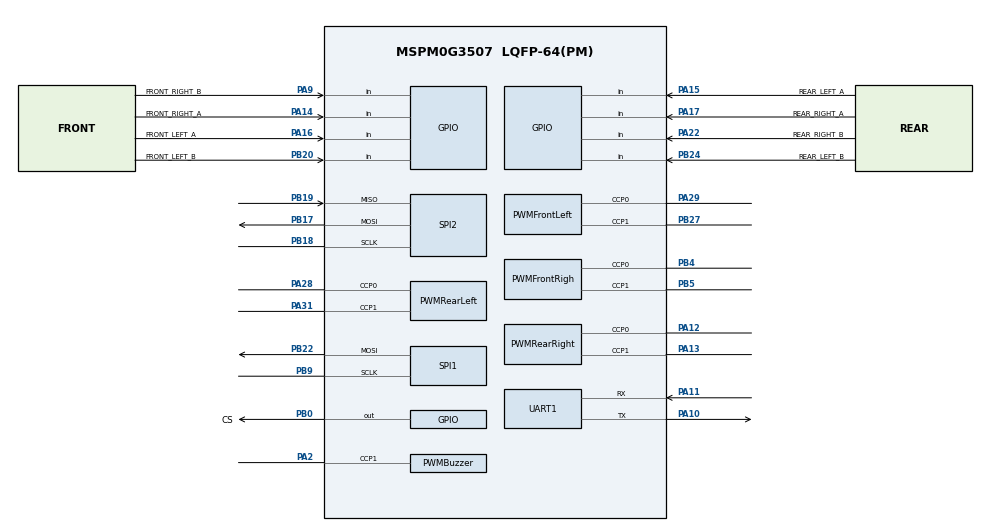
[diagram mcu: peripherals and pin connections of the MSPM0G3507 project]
/**
 * MSPM0G3507 application SysConfig source.
 * Generated files are written only to this project's Debug directory.
 * @cliArgs --device "MSPM0G350X" --package "LQFP-64(PM)" --part "Default" --product "mspm0_sdk@2.11.00.07"
 * @v2CliArgs --device "MSPM0G3507" --package "LQFP-64(PM)" --product "mspm0_sdk@2.11.00.07"
 */
const Board = scripting.addModule("/ti/driverlib/Board", {}, false);
const GPIO = scripting.addModule("/ti/driverlib/GPIO", {}, false);
const GPIO1 = GPIO.addInstance();
const GPIO2 = GPIO.addInstance();
const GPIO3 = GPIO.addInstance();
const PWM = scripting.addModule("/ti/driverlib/PWM", {}, false);
const PWMFrontLeft = PWM.addInstance();
const PWMFrontRight = PWM.addInstance();
const PWMRearLeft = PWM.addInstance();
const PWMRearRight = PWM.addInstance();
const PWMBuzzer = PWM.addInstance();
const SPI = scripting.addModule("/ti/driverlib/SPI", {}, false);
const SPI1 = SPI.addInstance();
const SPI2 = SPI.addInstance();
const SYSCTL = scripting.addModule("/ti/driverlib/SYSCTL");
const UART = scripting.addModule("/ti/driverlib/UART", {}, false);
const UART1 = UART.addInstance();
const hfxT = system.clockTree["HFXT"];
const pllQDiv = system.clockTree["PLL_QDIV"];
const hsclkMux = system.clockTree["HSCLKMUX"];
const ulpDiv = system.clockTree["UDIV"];

hfxT.inputFreq = 40;
hfxT.enable = true;
pllQDiv.multiplyValue = 5;
hsclkMux.inputSelect = "HSCLKMUX_SYSPLL0";
ulpDiv.divideValue = 2;

Board.configureUnused = true;
GPIO2.$name = "ENCODER";
GPIO2.associatedPins.create(8);
GPIO2.associatedPins[0].$name = "FRONT_LEFT_A";
GPIO2.associatedPins[0].direction = "INPUT";
GPIO2.associatedPins[0].interruptEn = true;
GPIO2.associatedPins[0].polarity = "RISE_FALL";
GPIO2.associatedPins[0].internalResistor = "PULL_UP";
GPIO2.associatedPins[0].pin.$assign = "PA16";
GPIO2.associatedPins[1].$name = "FRONT_LEFT_B";
GPIO2.associatedPins[1].direction = "INPUT";
GPIO2.associatedPins[1].internalResistor = "PULL_UP";
GPIO2.associatedPins[1].pin.$assign = "PB20";
GPIO2.associatedPins[2].$name = "FRONT_RIGHT_A";
GPIO2.associatedPins[2].direction = "INPUT";
GPIO2.associatedPins[2].interruptEn = true;
GPIO2.associatedPins[2].polarity = "RISE_FALL";
GPIO2.associatedPins[2].internalResistor = "PULL_UP";
GPIO2.associatedPins[2].pin.$assign = "PA14";
GPIO2.associatedPins[3].$name = "FRONT_RIGHT_B";
GPIO2.associatedPins[3].direction = "INPUT";
GPIO2.associatedPins[3].internalResistor = "PULL_UP";
GPIO2.associatedPins[3].pin.$assign = "PA9";
GPIO2.associatedPins[4].$name = "REAR_LEFT_A";
GPIO2.associatedPins[4].direction = "INPUT";
GPIO2.associatedPins[4].interruptEn = true;
GPIO2.associatedPins[4].polarity = "RISE_FALL";
GPIO2.associatedPins[4].internalResistor = "PULL_UP";
GPIO2.associatedPins[4].pin.$assign = "PA15";
GPIO2.associatedPins[5].$name = "REAR_LEFT_B";
GPIO2.associatedPins[5].direction = "INPUT";
GPIO2.associatedPins[5].internalResistor = "PULL_UP";
GPIO2.associatedPins[5].pin.$assign = "PB24";
GPIO2.associatedPins[6].$name = "REAR_RIGHT_A";
GPIO2.associatedPins[6].direction = "INPUT";
GPIO2.associatedPins[6].interruptEn = true;
GPIO2.associatedPins[6].polarity = "RISE_FALL";
GPIO2.associatedPins[6].internalResistor = "PULL_UP";
GPIO2.associatedPins[6].pin.$assign = "PA17";
GPIO2.associatedPins[7].$name = "REAR_RIGHT_B";
GPIO2.associatedPins[7].direction = "INPUT";
GPIO2.associatedPins[7].internalResistor = "PULL_UP";
GPIO2.associatedPins[7].pin.$assign = "PA22";

GPIO3.$name = "BMI160_CS";
GPIO3.associatedPins.create(1);
GPIO3.associatedPins[0].$name = "CS";
GPIO3.associatedPins[0].direction = "OUTPUT";
GPIO3.associatedPins[0].initialValue = "SET";
GPIO3.associatedPins[0].pin.$assign = "PB0";

PWMFrontLeft.$name = "MOTOR_FRONT_LEFT";
PWMFrontLeft.timerStartTimer = true;
PWMFrontLeft.pwmMode = "EDGE_ALIGN_UP";
PWMFrontLeft.clockPrescale = 2;
PWMFrontLeft.timerCount = 4000;
PWMFrontLeft.peripheral.$assign = "TIMG6";
PWMFrontLeft.peripheral.ccp0Pin.$assign = "PA29";
PWMFrontLeft.peripheral.ccp1Pin.$assign = "PB27";

PWMFrontRight.$name = "MOTOR_FRONT_RIGHT";
PWMFrontRight.timerStartTimer = true;
PWMFrontRight.pwmMode = "EDGE_ALIGN_UP";
PWMFrontRight.clockDivider = 2;
PWMFrontRight.timerCount = 4000;
PWMFrontRight.peripheral.$assign = "TIMA1";
PWMFrontRight.peripheral.ccp0Pin.$assign = "PB4";
PWMFrontRight.peripheral.ccp1Pin.$assign = "PB5";

PWMRearLeft.$name = "MOTOR_REAR_LEFT";
PWMRearLeft.timerStartTimer = true;
PWMRearLeft.pwmMode = "EDGE_ALIGN_UP";
PWMRearLeft.clockDivider = 2;
PWMRearLeft.timerCount = 4000;
PWMRearLeft.peripheral.$assign = "TIMG7";
PWMRearLeft.peripheral.ccp0Pin.$assign = "PA28";
PWMRearLeft.peripheral.ccp1Pin.$assign = "PA31";

PWMRearRight.$name = "MOTOR_REAR_RIGHT";
PWMRearRight.timerStartTimer = true;
PWMRearRight.pwmMode = "EDGE_ALIGN_UP";
PWMRearRight.timerCount = 4000;
PWMRearRight.peripheral.$assign = "TIMG0";
PWMRearRight.peripheral.ccp0Pin.$assign = "PA12";
PWMRearRight.peripheral.ccp1Pin.$assign = "PA13";

PWMBuzzer.$name = "BUZZER";
PWMBuzzer.timerStartTimer = true;
PWMBuzzer.pwmMode = "EDGE_ALIGN_UP";
PWMBuzzer.timerCount = 20000;
PWMBuzzer.peripheral.$assign = "TIMG8";
PWMBuzzer.peripheral.ccp1Pin.$assign = "PA2";

SPI1.$name = "SPI_WS2812";
SPI1.targetBitRate = 2666667;
SPI1.phase = "0";
SPI1.dataSize = 8;
SPI1.chipSelect = [];
SPI1.frameFormat = "MOTO3";
SPI1.peripheral.$assign = "SPI1";
SPI1.peripheral.sclkPin.$assign = "PB9";
SPI1.peripheral.mosiPin.$assign = "PB22";

SPI2.$name = "SPI_BMI160";
SPI2.targetBitRate = 8000000;
SPI2.polarity = "1";
SPI2.phase = "1";
SPI2.dataSize = 8;
SPI2.chipSelect = [];
SPI2.frameFormat = "MOTO3";
SPI2.peripheral.$assign = "SPI0";
SPI2.peripheral.sclkPin.$assign = "PB18";
SPI2.peripheral.mosiPin.$assign = "PB17";
SPI2.peripheral.misoPin.$assign = "PB19";
SYSCTL.clockTreeEn = true;
SYSCTL.forceDefaultClkConfig = true;
UART1.$name = "UART_0";
UART1.profile = "CONFIG_PROFILE_1";
UART1.targetBaudRate = 115200;
UART1.enableDMARX = false;
UART1.enableDMATX = false;
UART1.enableInternalLoopback = false;
UART1.enabledInterrupts = ["RX"];
UART1.enableFIFO = true;
UART1.peripheral.$assign = "UART0";
UART1.peripheral.rxPin.$assign = "PA11";
UART1.peripheral.txPin.$assign = "PA10";
